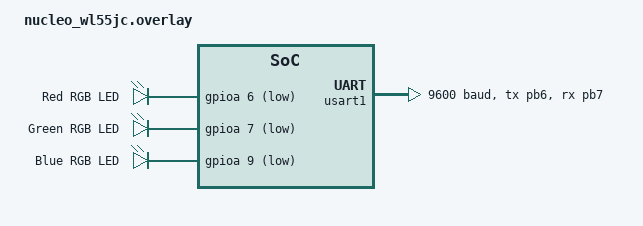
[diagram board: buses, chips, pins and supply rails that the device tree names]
#include <zephyr/dt-bindings/pinctrl/stm32-pinctrl.h>

/ {
    rgb_leds {
        compatible = "gpio-leds";

        rgb_red: rgb_0 {
            gpios = <&gpioa 6 GPIO_ACTIVE_LOW>;
            label = "Red RGB LED";
        };
        rgb_green: rgb_1 {
            gpios = <&gpioa 7 GPIO_ACTIVE_LOW>;
            label = "Green RGB LED";
        };
        rgb_blue: rgb_2 {
            gpios = <&gpioa 9 GPIO_ACTIVE_LOW>;
            label = "Blue RGB LED";
        };
    };

    aliases {
        red = &rgb_red;
        green = &rgb_green;
        blue = &rgb_blue;
        led0 = &blue_led_1; 	// This is LED1 as labeled STM32WL55JC board's 
		led1 = &green_led_2; 	// This is LED2 as labeled STM32WL55JC board's 
		led2 = &red_led_3; 	    // This is LED3 as labeled STM32WL55JC board's 
    };


};

&usart1 {
    status = "okay";
    current-speed = <9600>;
    pinctrl-0 = <&usart1_tx_pb6 &usart1_rx_pb7>;
    pinctrl-names = "default";
};
